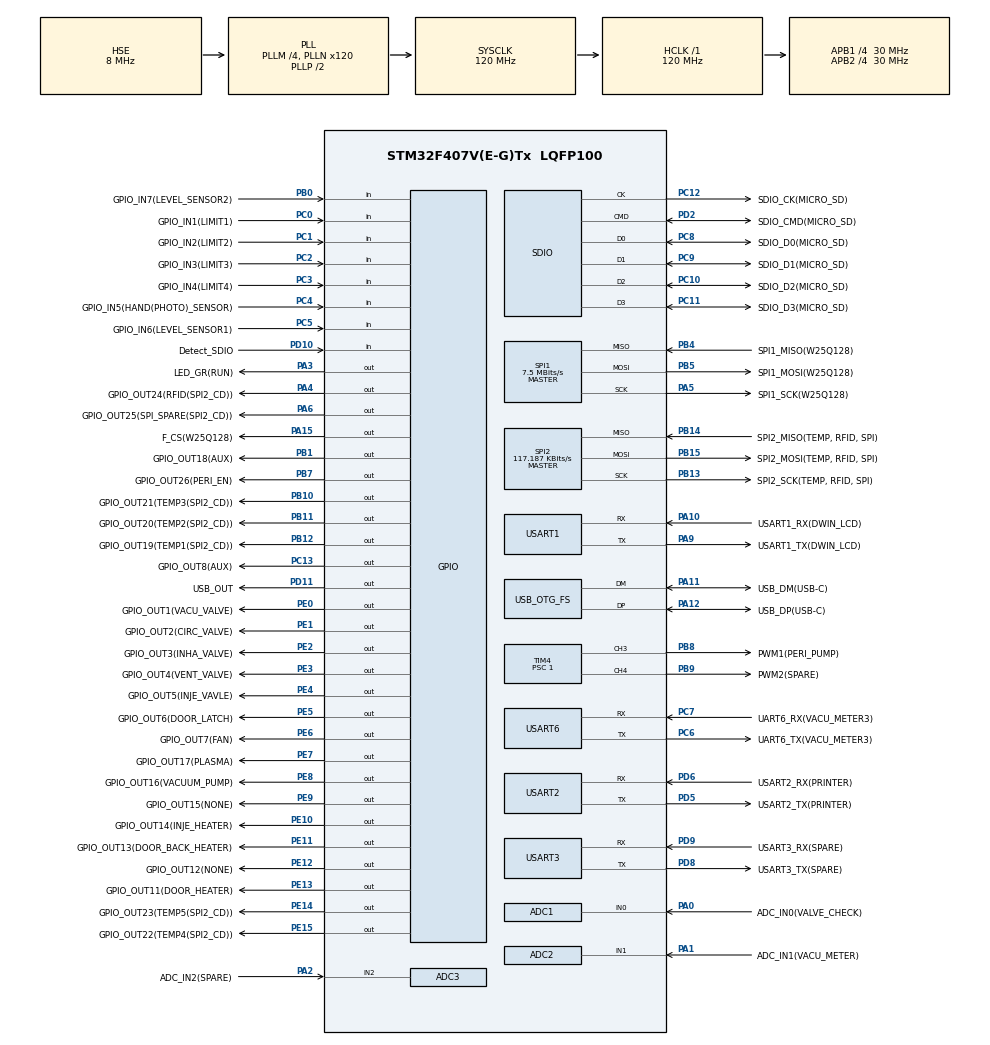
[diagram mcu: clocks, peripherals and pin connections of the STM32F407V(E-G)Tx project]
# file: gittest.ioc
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ADC1.Channel-3\#ChannelRegularConversion=ADC_CHANNEL_0
ADC1.Channel-4\#ChannelInjectedConversion=ADC_CHANNEL_0
ADC1.InjNumberOfConversion=1
ADC1.InjectedOffset-4\#ChannelInjectedConversion=0
ADC1.InjectedRank-4\#ChannelInjectedConversion=1
ADC1.NbrOfConversion=1
ADC1.NbrOfConversionFlag=1
ADC1.Rank-3\#ChannelRegularConversion=1
ADC1.SamplingTime-3\#ChannelRegularConversion=ADC_SAMPLETIME_3CYCLES
ADC1.SamplingTime-4\#ChannelInjectedConversion=ADC_SAMPLETIME_3CYCLES
ADC1.master=1
ADC2.Channel-5\#ChannelRegularConversion=ADC_CHANNEL_1
ADC2.Channel-6\#ChannelRegularConversion=ADC_CHANNEL_1
ADC2.Channel-7\#ChannelRegularConversion=ADC_CHANNEL_1
ADC2.Channel-8\#ChannelRegularConversion=ADC_CHANNEL_1
ADC2.Channel-9\#ChannelRegularConversion=ADC_CHANNEL_1
ADC2.ClockPrescaler=ADC_CLOCK_SYNC_PCLK_DIV2
ADC2.ContinuousConvMode=ENABLE
ADC2.DMAContinuousRequests=ENABLE
ADC2.NbrOfConversion=5
ADC2.NbrOfConversionFlag=1
ADC2.Rank-5\#ChannelRegularConversion=1
ADC2.Rank-6\#ChannelRegularConversion=2
ADC2.Rank-7\#ChannelRegularConversion=3
ADC2.Rank-8\#ChannelRegularConversion=4
ADC2.Rank-9\#ChannelRegularConversion=5
ADC2.SamplingTime-5\#ChannelRegularConversion=ADC_SAMPLETIME_15CYCLES
ADC2.SamplingTime-6\#ChannelRegularConversion=ADC_SAMPLETIME_15CYCLES
ADC2.SamplingTime-7\#ChannelRegularConversion=ADC_SAMPLETIME_15CYCLES
ADC2.SamplingTime-8\#ChannelRegularConversion=ADC_SAMPLETIME_15CYCLES
ADC2.SamplingTime-9\#ChannelRegularConversion=ADC_SAMPLETIME_15CYCLES
ADC2.ScanConvMode=ENABLE
ADC3.Channel-2\#ChannelRegularConversion=ADC_CHANNEL_2
ADC3.NbrOfConversionFlag=1
ADC3.Rank-2\#ChannelRegularConversion=1
ADC3.SamplingTime-2\#ChannelRegularConversion=ADC_SAMPLETIME_3CYCLES
Dma.ADC2.0.Direction=DMA_PERIPH_TO_MEMORY
Dma.ADC2.0.FIFOMode=DMA_FIFOMODE_DISABLE
Dma.ADC2.0.Instance=DMA2_Stream2
Dma.ADC2.0.MemDataAlignment=DMA_MDATAALIGN_WORD
Dma.ADC2.0.MemInc=DMA_MINC_ENABLE
Dma.ADC2.0.Mode=DMA_CIRCULAR
Dma.ADC2.0.PeriphDataAlignment=DMA_PDATAALIGN_WORD
Dma.ADC2.0.PeriphInc=DMA_PINC_DISABLE
Dma.ADC2.0.Priority=DMA_PRIORITY_LOW
Dma.Request0=ADC2
FATFS.BSP.number=1
FATFS._USE_LFN=1
FATFS0.BSP.STBoard=false
FATFS0.BSP.api=Unknown
FATFS0.BSP.instance=PD10
FATFS0.BSP.ip=GPIO
FATFS0.BSP.mode=Input
FATFS0.BSP.name=Detect_SDIO
FATFS0.BSP.solution=PD10
Mcu.Family=STM32F4
Mcu.Name=STM32F407V(E-G)Tx
Mcu.Package=LQFP100
NVIC.DMA2_Stream2_IRQn=true\:0\:0\:false\:false\:true\:false\:true\:true
NVIC.OTG_FS_IRQn=true\:0\:0\:false\:false\:true\:true\:true\:true
NVIC.PriorityGroup=NVIC_PRIORITYGROUP_4
NVIC.TIM7_IRQn=true\:0\:0\:false\:true\:true\:1\:true\:true\:true
NVIC.USART1_IRQn=true\:0\:0\:false\:true\:true\:2\:true\:true\:true
PA0-WKUP.GPIO_Label=ADC_IN0(VALVE_CHECK)
PA0-WKUP.Signal=ADCx_IN0
PA1.GPIO_Label=ADC_IN1(VACU_METER)
PA1.Signal=ADCx_IN1
PA10.GPIO_Label=USART1_RX(DWIN_LCD)
PA10.GPIO_PuPd=GPIO_PULLUP
PA10.Mode=Asynchronous
PA10.Signal=USART1_RX
PA11.GPIO_Label=USB_DM(USB-C)
PA11.GPIO_PuPd=GPIO_PULLUP
PA11.GPIO_Speed=GPIO_SPEED_FREQ_HIGH
PA11.Mode=Host_Only
PA11.Signal=USB_OTG_FS_DM
PA12.GPIO_Label=USB_DP(USB-C)
PA12.GPIO_PuPd=GPIO_PULLUP
PA12.GPIO_Speed=GPIO_SPEED_FREQ_HIGH
PA12.Mode=Host_Only
PA12.Signal=USB_OTG_FS_DP
PA13.Mode=Trace_Asynchronous_SW
PA13.Signal=SYS_JTMS-SWDIO
PA14.Mode=Trace_Asynchronous_SW
PA14.Signal=SYS_JTCK-SWCLK
PA15.GPIO_Label=F_CS(W25Q128)
PA15.Signal=GPIO_Output
PA2.GPIO_Label=ADC_IN2(SPARE)
PA2.Signal=ADCx_IN2
PA3.GPIO_Label=LED_GR(RUN)
PA3.Signal=GPIO_Output
PA4.GPIO_Label=GPIO_OUT24(RFID(SPI2_CD))
PA4.GPIO_PuPd=GPIO_PULLUP
PA4.GPIO_Speed=GPIO_SPEED_FREQ_VERY_HIGH
PA4.PinState=GPIO_PIN_SET
PA4.Signal=GPIO_Output
PA5.GPIO_Label=SPI1_SCK(W25Q128)
PA5.Mode=Full_Duplex_Master
PA5.Signal=SPI1_SCK
PA6.GPIO_Label=GPIO_OUT25(SPI_SPARE(SPI2_CD))
PA6.GPIO_PuPd=GPIO_PULLUP
PA6.GPIO_Speed=GPIO_SPEED_FREQ_VERY_HIGH
PA6.PinState=GPIO_PIN_SET
PA6.Signal=GPIO_Output
PA9.GPIO_Label=USART1_TX(DWIN_LCD)
PA9.GPIO_PuPd=GPIO_PULLUP
PA9.Mode=Asynchronous
PA9.Signal=USART1_TX
PB0.GPIO_Label=GPIO_IN7(LEVEL_SENSOR2)
PB0.Signal=GPIO_Input
PB1.GPIO_Label=GPIO_OUT18(AUX)
PB1.GPIO_ModeDefaultOutputPP=GPIO_MODE_OUTPUT_OD
PB1.PinState=GPIO_PIN_SET
PB1.Signal=GPIO_Output
PB10.GPIO_Label=GPIO_OUT21(TEMP3(SPI2_CD))
PB10.GPIO_PuPd=GPIO_PULLUP
PB10.GPIO_Speed=GPIO_SPEED_FREQ_VERY_HIGH
PB10.PinState=GPIO_PIN_SET
PB10.Signal=GPIO_Output
PB11.GPIO_Label=GPIO_OUT20(TEMP2(SPI2_CD))
PB11.GPIO_PuPd=GPIO_PULLUP
PB11.GPIO_Speed=GPIO_SPEED_FREQ_VERY_HIGH
PB11.PinState=GPIO_PIN_SET
PB11.Signal=GPIO_Output
PB12.GPIO_Label=GPIO_OUT19(TEMP1(SPI2_CD))
PB12.GPIO_PuPd=GPIO_PULLUP
PB12.GPIO_Speed=GPIO_SPEED_FREQ_VERY_HIGH
PB12.PinState=GPIO_PIN_SET
PB12.Signal=GPIO_Output
PB13.GPIO_Label=SPI2_SCK(TEMP, RFID, SPI)
PB13.Mode=Full_Duplex_Master
PB13.Signal=SPI2_SCK
PB14.GPIO_Label=SPI2_MISO(TEMP, RFID, SPI)
PB14.GPIO_PuPd=GPIO_PULLUP
PB14.Mode=Full_Duplex_Master
PB14.Signal=SPI2_MISO
PB15.GPIO_Label=SPI2_MOSI(TEMP, RFID, SPI)
PB15.GPIO_PuPd=GPIO_PULLUP
PB15.Mode=Full_Duplex_Master
PB15.Signal=SPI2_MOSI
PB3.Mode=Trace_Asynchronous_SW
PB3.Signal=SYS_JTDO-SWO
PB4.GPIO_Label=SPI1_MISO(W25Q128)
PB4.Mode=Full_Duplex_Master
PB4.Signal=SPI1_MISO
PB5.GPIO_Label=SPI1_MOSI(W25Q128)
PB5.Mode=Full_Duplex_Master
PB5.Signal=SPI1_MOSI
PB7.GPIO_Label=GPIO_OUT26(PERI_EN)
PB7.GPIO_ModeDefaultOutputPP=GPIO_MODE_OUTPUT_OD
PB7.PinState=GPIO_PIN_SET
PB7.Signal=GPIO_Output
PB8.GPIO_Label=PWM1(PERI_PUMP)
PB8.GPIO_ModeDefaultPP=GPIO_MODE_AF_PP
PB8.Signal=S_TIM4_CH3
PB9.GPIO_Label=PWM2(SPARE)
PB9.Signal=S_TIM4_CH4
PC0.GPIO_Label=GPIO_IN1(LIMIT1)
PC0.Signal=GPIO_Input
PC1.GPIO_Label=GPIO_IN2(LIMIT2)
PC1.Signal=GPIO_Input
PC10.GPIO_Label=SDIO_D2(MICRO_SD)
PC10.GPIO_PuPd=GPIO_PULLUP
PC10.Mode=SD_4_bits_Wide_bus
PC10.Signal=SDIO_D2
PC11.GPIO_Label=SDIO_D3(MICRO_SD)
PC11.GPIO_PuPd=GPIO_PULLUP
PC11.Mode=SD_4_bits_Wide_bus
PC11.Signal=SDIO_D3
PC12.GPIO_Label=SDIO_CK(MICRO_SD)
PC12.GPIO_PuPd=GPIO_PULLUP
PC12.Mode=SD_4_bits_Wide_bus
PC12.Signal=SDIO_CK
PC13-ANTI_TAMP.GPIO_Label=GPIO_OUT8(AUX)
PC13-ANTI_TAMP.Signal=GPIO_Output
PC2.GPIO_Label=GPIO_IN3(LIMIT3)
PC2.Signal=GPIO_Input
PC3.GPIO_Label=GPIO_IN4(LIMIT4)
PC3.Signal=GPIO_Input
PC4.GPIO_Label=GPIO_IN5(HAND(PHOTO)_SENSOR)
PC4.Signal=GPIO_Input
PC5.GPIO_Label=GPIO_IN6(LEVEL_SENSOR1)
PC5.Signal=GPIO_Input
PC6.GPIO_Label=UART6_TX(VACU_METER3)
PC6.Mode=Asynchronous
PC6.Signal=USART6_TX
PC7.GPIO_Label=UART6_RX(VACU_METER3)
PC7.Mode=Asynchronous
PC7.Signal=USART6_RX
PC8.GPIO_Label=SDIO_D0(MICRO_SD)
PC8.GPIO_PuPd=GPIO_PULLUP
PC8.Mode=SD_4_bits_Wide_bus
PC8.Signal=SDIO_D0
PC9.GPIO_Label=SDIO_D1(MICRO_SD)
PC9.GPIO_PuPd=GPIO_PULLUP
PC9.Mode=SD_4_bits_Wide_bus
PC9.Signal=SDIO_D1
PD10.GPIO_Label=Detect_SDIO
PD10.Signal=GPIO_Input
PD11.GPIO_Label=USB_OUT
PD11.Signal=GPIO_Output
PD2.GPIO_Label=SDIO_CMD(MICRO_SD)
PD2.GPIO_PuPd=GPIO_PULLUP
PD2.Mode=SD_4_bits_Wide_bus
PD2.Signal=SDIO_CMD
PD5.GPIO_Label=USART2_TX(PRINTER)
PD5.GPIO_PuPd=GPIO_PULLUP
PD5.Mode=Asynchronous
PD5.Signal=USART2_TX
PD6.GPIO_Label=USART2_RX(PRINTER)
PD6.GPIO_PuPd=GPIO_PULLUP
PD6.Mode=Asynchronous
PD6.Signal=USART2_RX
PD8.GPIO_Label=USART3_TX(SPARE)
PD8.Mode=Asynchronous
PD8.Signal=USART3_TX
PD9.GPIO_Label=USART3_RX(SPARE)
PD9.Mode=Asynchronous
PD9.Signal=USART3_RX
PE0.GPIO_Label=GPIO_OUT1(VACU_VALVE)
PE0.GPIO_ModeDefaultOutputPP=GPIO_MODE_OUTPUT_PP
PE0.GPIO_Speed=GPIO_SPEED_FREQ_VERY_HIGH
PE0.Signal=GPIO_Output
PE1.GPIO_Label=GPIO_OUT2(CIRC_VALVE)
PE1.Signal=GPIO_Output
PE10.GPIO_Label=GPIO_OUT14(INJE_HEATER)
PE10.GPIO_ModeDefaultOutputPP=GPIO_MODE_OUTPUT_OD
PE10.PinState=GPIO_PIN_SET
PE10.Signal=GPIO_Output
PE11.GPIO_Label=GPIO_OUT13(DOOR_BACK_HEATER)
PE11.GPIO_ModeDefaultOutputPP=GPIO_MODE_OUTPUT_OD
PE11.PinState=GPIO_PIN_SET
PE11.Signal=GPIO_Output
PE12.GPIO_Label=GPIO_OUT12(NONE)
PE12.GPIO_ModeDefaultOutputPP=GPIO_MODE_OUTPUT_OD
PE12.PinState=GPIO_PIN_SET
PE12.Signal=GPIO_Output
PE13.GPIO_Label=GPIO_OUT11(DOOR_HEATER)
PE13.GPIO_ModeDefaultOutputPP=GPIO_MODE_OUTPUT_OD
PE13.PinState=GPIO_PIN_SET
PE13.Signal=GPIO_Output
PE14.GPIO_Label=GPIO_OUT23(TEMP5(SPI2_CD))
PE14.GPIO_PuPd=GPIO_PULLUP
PE14.GPIO_Speed=GPIO_SPEED_FREQ_VERY_HIGH
PE14.PinState=GPIO_PIN_SET
PE14.Signal=GPIO_Output
PE15.GPIO_Label=GPIO_OUT22(TEMP4(SPI2_CD))
PE15.GPIO_PuPd=GPIO_PULLUP
PE15.GPIO_Speed=GPIO_SPEED_FREQ_VERY_HIGH
PE15.PinState=GPIO_PIN_SET
PE15.Signal=GPIO_Output
PE2.GPIO_Label=GPIO_OUT3(INHA_VALVE)
PE2.Signal=GPIO_Output
PE3.GPIO_Label=GPIO_OUT4(VENT_VALVE)
PE3.Signal=GPIO_Output
PE4.GPIO_Label=GPIO_OUT5(INJE_VAVLE)
PE4.Signal=GPIO_Output
PE5.GPIO_Label=GPIO_OUT6(DOOR_LATCH)
PE5.Signal=GPIO_Output
PE6.GPIO_Label=GPIO_OUT7(FAN)
PE6.Signal=GPIO_Output
PE7.GPIO_Label=GPIO_OUT17(PLASMA)
PE7.GPIO_ModeDefaultOutputPP=GPIO_MODE_OUTPUT_OD
PE7.PinState=GPIO_PIN_SET
PE7.Signal=GPIO_Output
PE8.GPIO_Label=GPIO_OUT16(VACUUM_PUMP)
PE8.GPIO_ModeDefaultOutputPP=GPIO_MODE_OUTPUT_OD
PE8.PinState=GPIO_PIN_SET
PE8.Signal=GPIO_Output
PE9.GPIO_Label=GPIO_OUT15(NONE)
PE9.GPIO_ModeDefaultOutputPP=GPIO_MODE_OUTPUT_OD
PE9.PinState=GPIO_PIN_SET
PE9.Signal=GPIO_Output
PH0-OSC_IN.Mode=HSE-External-Oscillator
PH0-OSC_IN.Signal=RCC_OSC_IN
PH1-OSC_OUT.Mode=HSE-External-Oscillator
PH1-OSC_OUT.Signal=RCC_OSC_OUT
ProjectManager.HeapSize=0x200
ProjectManager.StackSize=0x400
ProjectManager.TargetToolchain=STM32CubeIDE
RCC.48MHZClocksFreq_Value=48000000
RCC.AHBFreq_Value=120000000
RCC.APB1CLKDivider=RCC_HCLK_DIV4
RCC.APB1Freq_Value=30000000
RCC.APB1TimFreq_Value=60000000
RCC.APB2CLKDivider=RCC_HCLK_DIV4
RCC.APB2Freq_Value=30000000
RCC.APB2TimFreq_Value=60000000
RCC.CortexFreq_Value=120000000
RCC.HCLKFreq_Value=120000000
RCC.HSE_VALUE=8000000
RCC.HSI_VALUE=16000000
RCC.LSE_VALUE=32768
RCC.PLLM=4
RCC.PLLN=120
RCC.PLLQ=5
RCC.SYSCLKFreq_VALUE=120000000
RCC.SYSCLKSource=RCC_SYSCLKSOURCE_PLLCLK
RCC.VCOOutputFreq_Value=240000000
SDIO.ClockDiv=3
SH.ADCx_IN0.0=ADC1_IN0,IN0
SH.ADCx_IN1.0=ADC2_IN1,IN1
SH.ADCx_IN2.0=ADC3_IN2,IN2
SH.S_TIM4_CH3.0=TIM4_CH3,PWM Generation3 CH3
SH.S_TIM4_CH4.0=TIM4_CH4,PWM Generation4 CH4
SPI1.BaudRatePrescaler=SPI_BAUDRATEPRESCALER_4
SPI1.CalculateBaudRate=7.5 MBits/s
SPI1.Direction=SPI_DIRECTION_2LINES
SPI1.Mode=SPI_MODE_MASTER
SPI1.VirtualType=VM_MASTER
SPI2.BaudRatePrescaler=SPI_BAUDRATEPRESCALER_256
SPI2.CalculateBaudRate=117.187 KBits/s
SPI2.Direction=SPI_DIRECTION_2LINES
SPI2.Mode=SPI_MODE_MASTER
SPI2.VirtualType=VM_MASTER
TIM4.Channel-PWM\ Generation3\ CH3=TIM_CHANNEL_3
TIM4.Channel-PWM\ Generation4\ CH4=TIM_CHANNEL_4
TIM4.Period=20000-1
TIM4.Prescaler=1
TIM4.Pulse-PWM\ Generation3\ CH3=4000-1
TIM4.Pulse-PWM\ Generation4\ CH4=4000-1
TIM7.Period=6000-1
TIM7.Prescaler=10-1
USART1.VirtualMode=VM_ASYNC
USART2.VirtualMode=VM_ASYNC
USART3.VirtualMode=VM_ASYNC
USART6.VirtualMode=VM_ASYNC
USB_HOST.BSP.number=1
USB_HOST.SW_VBUS_DRIVE_MSC_FS=false
USB_HOST.USBH_HandleTypeDef-MSC_FS=hUsbHostFS
USB_HOST.VirtualModeFS=Msc
USB_HOST0.BSP.STBoard=false
USB_HOST0.BSP.api=Unknown
USB_HOST0.BSP.condition=SW_VBUS_DRIVE_MSC_FS \= false
USB_HOST0.BSP.instance=PD11
USB_HOST0.BSP.ip=GPIO
USB_HOST0.BSP.mode=Output
USB_HOST0.BSP.name=Drive_VBUS_FS
USB_HOST0.BSP.solution=PD11
USB_OTG_FS.VirtualMode=Host_Only
USB_OTG_FS.phy_itface=HCD_PHY_EMBEDDED
VP_CRC_VS_CRC.Mode=CRC_Activate
VP_FATFS_VS_SDIO.Mode=SDIO
VP_FATFS_VS_USB.Mode=USB
VP_RTC_VS_RTC_Activate.Mode=RTC_Enabled
VP_RTC_VS_RTC_Calendar.Mode=RTC_Calendar
VP_TIM7_VS_ClockSourceINT.Mode=Enable_Timer
VP_USB_HOST_VS_USB_HOST_MSC_FS.Mode=MSC_FS
board=custom

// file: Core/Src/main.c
/* USER CODE BEGIN Header */
/**
  ******************************************************************************
  * @file           : main.c
  * @brief          : Main program body
  ******************************************************************************
  * @attention
  *
  * Copyright (c) 2024 STMicroelectronics.
  * All rights reserved.
  *
  * This software is licensed under terms that can be found in the LICENSE file
  * in the root directory of this software component.
  * If no LICENSE file comes with this software, it is provided AS-IS.
  *
  ******************************************************************************
  */
/* USER CODE END Header */
#include "main.h"
#include "fatfs.h"
#include "usb_host.h"

/* USER CODE BEGIN Includes */
//이런식으로 수정하면 되나?
/* USER CODE END Includes */

ADC_HandleTypeDef hadc1;
ADC_HandleTypeDef hadc2;
ADC_HandleTypeDef hadc3;
DMA_HandleTypeDef hdma_adc2;

CRC_HandleTypeDef hcrc;

RTC_HandleTypeDef hrtc;

SD_HandleTypeDef hsd;

SPI_HandleTypeDef hspi1;
SPI_HandleTypeDef hspi2;

TIM_HandleTypeDef htim4;
TIM_HandleTypeDef htim7;

UART_HandleTypeDef huart1;
UART_HandleTypeDef huart2;
UART_HandleTypeDef huart3;
UART_HandleTypeDef huart6;

void SystemClock_Config(void);
static void MX_GPIO_Init(void);
static void MX_DMA_Init(void);
static void MX_RTC_Init(void);
static void MX_SDIO_SD_Init(void);
static void MX_SPI1_Init(void);
static void MX_SPI2_Init(void);
static void MX_TIM4_Init(void);
static void MX_TIM7_Init(void);
static void MX_USART1_UART_Init(void);
static void MX_USART2_UART_Init(void);
static void MX_USART3_UART_Init(void);
static void MX_USART6_UART_Init(void);
static void MX_ADC2_Init(void);
static void MX_ADC1_Init(void);
static void MX_ADC3_Init(void);
static void MX_CRC_Init(void);
static void MX_NVIC_Init(void);
void MX_USB_HOST_Process(void);

int main(void)
{

  /* MCU Configuration--------------------------------------------------------*/

  /* Reset of all peripherals, Initializes the Flash interface and the Systick. */
  HAL_Init();

  /* Configure the system clock */
  SystemClock_Config();

  /* Initialize all configured peripherals */
  MX_GPIO_Init();
  MX_DMA_Init();
  MX_RTC_Init();
  MX_SDIO_SD_Init();
  MX_SPI1_Init();
  MX_SPI2_Init();
  MX_TIM4_Init();
  MX_TIM7_Init();
  MX_USART1_UART_Init();
  MX_USART2_UART_Init();
  MX_USART3_UART_Init();
  MX_USART6_UART_Init();
  MX_ADC2_Init();
  MX_ADC1_Init();
  MX_ADC3_Init();
  MX_FATFS_Init();
  MX_CRC_Init();
  MX_USB_HOST_Init();

  /* Initialize interrupts */
  MX_NVIC_Init();

  /* Infinite loop */
  while (1)
  {
    MX_USB_HOST_Process();

  }
}

void SystemClock_Config(void)
{
  RCC_OscInitTypeDef RCC_OscInitStruct = {0};
  RCC_ClkInitTypeDef RCC_ClkInitStruct = {0};

  /** Configure the main internal regulator output voltage
  */
  __HAL_RCC_PWR_CLK_ENABLE();
  __HAL_PWR_VOLTAGESCALING_CONFIG(PWR_REGULATOR_VOLTAGE_SCALE1);

  /** Initializes the RCC Oscillators according to the specified parameters
  * in the RCC_OscInitTypeDef structure.
  */
  RCC_OscInitStruct.OscillatorType = RCC_OSCILLATORTYPE_LSI|RCC_OSCILLATORTYPE_HSE;
  RCC_OscInitStruct.HSEState = RCC_HSE_ON;
  RCC_OscInitStruct.LSIState = RCC_LSI_ON;
  RCC_OscInitStruct.PLL.PLLState = RCC_PLL_ON;
  RCC_OscInitStruct.PLL.PLLSource = RCC_PLLSOURCE_HSE;
  RCC_OscInitStruct.PLL.PLLM = 4;
  RCC_OscInitStruct.PLL.PLLN = 120;
  RCC_OscInitStruct.PLL.PLLP = RCC_PLLP_DIV2;
  RCC_OscInitStruct.PLL.PLLQ = 5;
  if (HAL_RCC_OscConfig(&RCC_OscInitStruct) != HAL_OK)
  {
    Error_Handler();
  }

  /** Initializes the CPU, AHB and APB buses clocks
  */
  RCC_ClkInitStruct.ClockType = RCC_CLOCKTYPE_HCLK|RCC_CLOCKTYPE_SYSCLK
                              |RCC_CLOCKTYPE_PCLK1|RCC_CLOCKTYPE_PCLK2;
  RCC_ClkInitStruct.SYSCLKSource = RCC_SYSCLKSOURCE_PLLCLK;
  RCC_ClkInitStruct.AHBCLKDivider = RCC_SYSCLK_DIV1;
  RCC_ClkInitStruct.APB1CLKDivider = RCC_HCLK_DIV4;
  RCC_ClkInitStruct.APB2CLKDivider = RCC_HCLK_DIV4;

  if (HAL_RCC_ClockConfig(&RCC_ClkInitStruct, FLASH_LATENCY_3) != HAL_OK)
  {
    Error_Handler();
  }
}

/**
  * @brief NVIC Configuration.
  * @retval None
  */
static void MX_NVIC_Init(void)
{
  /* TIM7_IRQn interrupt configuration */
  HAL_NVIC_SetPriority(TIM7_IRQn, 0, 0);
  HAL_NVIC_EnableIRQ(TIM7_IRQn);
  /* USART1_IRQn interrupt configuration */
  HAL_NVIC_SetPriority(USART1_IRQn, 0, 0);
  HAL_NVIC_EnableIRQ(USART1_IRQn);
}

static void MX_ADC1_Init(void)
{

  ADC_ChannelConfTypeDef sConfig = {0};
  ADC_InjectionConfTypeDef sConfigInjected = {0};

  /** Configure the global features of the ADC (Clock, Resolution, Data Alignment and number of conversion)
  */
  hadc1.Instance = ADC1;
  hadc1.Init.ClockPrescaler = ADC_CLOCK_SYNC_PCLK_DIV2;
  hadc1.Init.Resolution = ADC_RESOLUTION_12B;
  hadc1.Init.ScanConvMode = DISABLE;
  hadc1.Init.ContinuousConvMode = DISABLE;
  hadc1.Init.DiscontinuousConvMode = DISABLE;
  hadc1.Init.ExternalTrigConvEdge = ADC_EXTERNALTRIGCONVEDGE_NONE;
  hadc1.Init.ExternalTrigConv = ADC_SOFTWARE_START;
  hadc1.Init.DataAlign = ADC_DATAALIGN_RIGHT;
  hadc1.Init.NbrOfConversion = 1;
  hadc1.Init.DMAContinuousRequests = DISABLE;
  hadc1.Init.EOCSelection = ADC_EOC_SINGLE_CONV;
  if (HAL_ADC_Init(&hadc1) != HAL_OK)
  {
    Error_Handler();
  }

  /** Configure for the selected ADC regular channel its corresponding rank in the sequencer and its sample time.
  */
  sConfig.Channel = ADC_CHANNEL_0;
  sConfig.Rank = 1;
  sConfig.SamplingTime = ADC_SAMPLETIME_3CYCLES;
  if (HAL_ADC_ConfigChannel(&hadc1, &sConfig) != HAL_OK)
  {
    Error_Handler();
  }

  /** Configures for the selected ADC injected channel its corresponding rank in the sequencer and its sample time
  */
  sConfigInjected.InjectedChannel = ADC_CHANNEL_0;
  sConfigInjected.InjectedRank = 1;
  sConfigInjected.InjectedNbrOfConversion = 1;
  sConfigInjected.InjectedSamplingTime = ADC_SAMPLETIME_3CYCLES;
  sConfigInjected.ExternalTrigInjecConvEdge = ADC_EXTERNALTRIGINJECCONVEDGE_NONE;
  sConfigInjected.ExternalTrigInjecConv = ADC_INJECTED_SOFTWARE_START;
  sConfigInjected.AutoInjectedConv = DISABLE;
  sConfigInjected.InjectedDiscontinuousConvMode = DISABLE;
  sConfigInjected.InjectedOffset = 0;
  if (HAL_ADCEx_InjectedConfigChannel(&hadc1, &sConfigInjected) != HAL_OK)
  {
    Error_Handler();
  }

}

static void MX_ADC2_Init(void)
{

  ADC_ChannelConfTypeDef sConfig = {0};

  /** Configure the global features of the ADC (Clock, Resolution, Data Alignment and number of conversion)
  */
  hadc2.Instance = ADC2;
  hadc2.Init.ClockPrescaler = ADC_CLOCK_SYNC_PCLK_DIV2;
  hadc2.Init.Resolution = ADC_RESOLUTION_12B;
  hadc2.Init.ScanConvMode = ENABLE;
  hadc2.Init.ContinuousConvMode = ENABLE;
  hadc2.Init.DiscontinuousConvMode = DISABLE;
  hadc2.Init.ExternalTrigConvEdge = ADC_EXTERNALTRIGCONVEDGE_NONE;
  hadc2.Init.ExternalTrigConv = ADC_SOFTWARE_START;
  hadc2.Init.DataAlign = ADC_DATAALIGN_RIGHT;
  hadc2.Init.NbrOfConversion = 5;
  hadc2.Init.DMAContinuousRequests = ENABLE;
  hadc2.Init.EOCSelection = ADC_EOC_SINGLE_CONV;
  if (HAL_ADC_Init(&hadc2) != HAL_OK)
  {
    Error_Handler();
  }

  /** Configure for the selected ADC regular channel its corresponding rank in the sequencer and its sample time.
  */
  sConfig.Channel = ADC_CHANNEL_1;
  sConfig.Rank = 1;
  sConfig.SamplingTime = ADC_SAMPLETIME_15CYCLES;
  if (HAL_ADC_ConfigChannel(&hadc2, &sConfig) != HAL_OK)
  {
    Error_Handler();
  }

  /** Configure for the selected ADC regular channel its corresponding rank in the sequencer and its sample time.
  */
  sConfig.Rank = 2;
  if (HAL_ADC_ConfigChannel(&hadc2, &sConfig) != HAL_OK)
  {
    Error_Handler();
  }

  /** Configure for the selected ADC regular channel its corresponding rank in the sequencer and its sample time.
  */
  sConfig.Rank = 3;
  if (HAL_ADC_ConfigChannel(&hadc2, &sConfig) != HAL_OK)
  {
    Error_Handler();
  }

  /** Configure for the selected ADC regular channel its corresponding rank in the sequencer and its sample time.
  */
  sConfig.Rank = 4;
  if (HAL_ADC_ConfigChannel(&hadc2, &sConfig) != HAL_OK)
  {
    Error_Handler();
  }

  /** Configure for the selected ADC regular channel its corresponding rank in the sequencer and its sample time.
  */
  sConfig.Rank = 5;
  if (HAL_ADC_ConfigChannel(&hadc2, &sConfig) != HAL_OK)
  {
    Error_Handler();
  }

}

static void MX_ADC3_Init(void)
{

  ADC_ChannelConfTypeDef sConfig = {0};

  /** Configure the global features of the ADC (Clock, Resolution, Data Alignment and number of conversion)
  */
  hadc3.Instance = ADC3;
  hadc3.Init.ClockPrescaler = ADC_CLOCK_SYNC_PCLK_DIV2;
  hadc3.Init.Resolution = ADC_RESOLUTION_12B;
  hadc3.Init.ScanConvMode = DISABLE;
  hadc3.Init.ContinuousConvMode = DISABLE;
  hadc3.Init.DiscontinuousConvMode = DISABLE;
  hadc3.Init.ExternalTrigConvEdge = ADC_EXTERNALTRIGCONVEDGE_NONE;
  hadc3.Init.ExternalTrigConv = ADC_SOFTWARE_START;
  hadc3.Init.DataAlign = ADC_DATAALIGN_RIGHT;
  hadc3.Init.NbrOfConversion = 1;
  hadc3.Init.DMAContinuousRequests = DISABLE;
  hadc3.Init.EOCSelection = ADC_EOC_SINGLE_CONV;
  if (HAL_ADC_Init(&hadc3) != HAL_OK)
  {
    Error_Handler();
  }

  /** Configure for the selected ADC regular channel its corresponding rank in the sequencer and its sample time.
  */
  sConfig.Channel = ADC_CHANNEL_2;
  sConfig.Rank = 1;
  sConfig.SamplingTime = ADC_SAMPLETIME_3CYCLES;
  if (HAL_ADC_ConfigChannel(&hadc3, &sConfig) != HAL_OK)
  {
    Error_Handler();
  }

}

static void MX_CRC_Init(void)
{

  hcrc.Instance = CRC;
  if (HAL_CRC_Init(&hcrc) != HAL_OK)
  {
    Error_Handler();
  }

}

static void MX_RTC_Init(void)
{

  RTC_TimeTypeDef sTime = {0};
  RTC_DateTypeDef sDate = {0};

  /** Initialize RTC Only
  */
  hrtc.Instance = RTC;
  hrtc.Init.HourFormat = RTC_HOURFORMAT_24;
  hrtc.Init.AsynchPrediv = 127;
  hrtc.Init.SynchPrediv = 255;
  hrtc.Init.OutPut = RTC_OUTPUT_DISABLE;
  hrtc.Init.OutPutPolarity = RTC_OUTPUT_POLARITY_HIGH;
  hrtc.Init.OutPutType = RTC_OUTPUT_TYPE_OPENDRAIN;
  if (HAL_RTC_Init(&hrtc) != HAL_OK)
  {
    Error_Handler();
  }

  /** Initialize RTC and set the Time and Date
  */
  sTime.Hours = 0x0;
  sTime.Minutes = 0x0;
  sTime.Seconds = 0x0;
  sTime.DayLightSaving = RTC_DAYLIGHTSAVING_NONE;
  sTime.StoreOperation = RTC_STOREOPERATION_RESET;
  if (HAL_RTC_SetTime(&hrtc, &sTime, RTC_FORMAT_BCD) != HAL_OK)
  {
    Error_Handler();
  }
  sDate.WeekDay = RTC_WEEKDAY_MONDAY;
  sDate.Month = RTC_MONTH_JANUARY;
  sDate.Date = 0x1;
  sDate.Year = 0x0;

  if (HAL_RTC_SetDate(&hrtc, &sDate, RTC_FORMAT_BCD) != HAL_OK)
  {
    Error_Handler();
  }

}

static void MX_SDIO_SD_Init(void)
{

  hsd.Instance = SDIO;
  hsd.Init.ClockEdge = SDIO_CLOCK_EDGE_RISING;
  hsd.Init.ClockBypass = SDIO_CLOCK_BYPASS_DISABLE;
  hsd.Init.ClockPowerSave = SDIO_CLOCK_POWER_SAVE_DISABLE;
  hsd.Init.BusWide = SDIO_BUS_WIDE_4B;
  hsd.Init.HardwareFlowControl = SDIO_HARDWARE_FLOW_CONTROL_DISABLE;
  hsd.Init.ClockDiv = 3;

}

static void MX_SPI1_Init(void)
{

  /* SPI1 parameter configuration*/
  hspi1.Instance = SPI1;
  hspi1.Init.Mode = SPI_MODE_MASTER;
  hspi1.Init.Direction = SPI_DIRECTION_2LINES;
  hspi1.Init.DataSize = SPI_DATASIZE_8BIT;
  hspi1.Init.CLKPolarity = SPI_POLARITY_LOW;
  hspi1.Init.CLKPhase = SPI_PHASE_1EDGE;
  hspi1.Init.NSS = SPI_NSS_SOFT;
  hspi1.Init.BaudRatePrescaler = SPI_BAUDRATEPRESCALER_4;
  hspi1.Init.FirstBit = SPI_FIRSTBIT_MSB;
  hspi1.Init.TIMode = SPI_TIMODE_DISABLE;
  hspi1.Init.CRCCalculation = SPI_CRCCALCULATION_DISABLE;
  hspi1.Init.CRCPolynomial = 10;
  if (HAL_SPI_Init(&hspi1) != HAL_OK)
  {
    Error_Handler();
  }

}

static void MX_SPI2_Init(void)
{

  /* SPI2 parameter configuration*/
  hspi2.Instance = SPI2;
  hspi2.Init.Mode = SPI_MODE_MASTER;
  hspi2.Init.Direction = SPI_DIRECTION_2LINES;
  hspi2.Init.DataSize = SPI_DATASIZE_8BIT;
  hspi2.Init.CLKPolarity = SPI_POLARITY_LOW;
  hspi2.Init.CLKPhase = SPI_PHASE_1EDGE;
  hspi2.Init.NSS = SPI_NSS_SOFT;
  hspi2.Init.BaudRatePrescaler = SPI_BAUDRATEPRESCALER_256;
  hspi2.Init.FirstBit = SPI_FIRSTBIT_MSB;
  hspi2.Init.TIMode = SPI_TIMODE_DISABLE;
  hspi2.Init.CRCCalculation = SPI_CRCCALCULATION_DISABLE;
  hspi2.Init.CRCPolynomial = 10;
  if (HAL_SPI_Init(&hspi2) != HAL_OK)
  {
    Error_Handler();
  }

}

static void MX_TIM4_Init(void)
{

  TIM_MasterConfigTypeDef sMasterConfig = {0};
  TIM_OC_InitTypeDef sConfigOC = {0};

  htim4.Instance = TIM4;
  htim4.Init.Prescaler = 1;
  htim4.Init.CounterMode = TIM_COUNTERMODE_UP;
  htim4.Init.Period = 20000-1;
  htim4.Init.ClockDivision = TIM_CLOCKDIVISION_DIV1;
  htim4.Init.AutoReloadPreload = TIM_AUTORELOAD_PRELOAD_DISABLE;
  if (HAL_TIM_PWM_Init(&htim4) != HAL_OK)
  {
    Error_Handler();
  }
  sMasterConfig.MasterOutputTrigger = TIM_TRGO_RESET;
  sMasterConfig.MasterSlaveMode = TIM_MASTERSLAVEMODE_DISABLE;
  if (HAL_TIMEx_MasterConfigSynchronization(&htim4, &sMasterConfig) != HAL_OK)
  {
    Error_Handler();
  }
  sConfigOC.OCMode = TIM_OCMODE_PWM1;
  sConfigOC.Pulse = 4000-1;
  sConfigOC.OCPolarity = TIM_OCPOLARITY_HIGH;
  sConfigOC.OCFastMode = TIM_OCFAST_DISABLE;
  if (HAL_TIM_PWM_ConfigChannel(&htim4, &sConfigOC, TIM_CHANNEL_3) != HAL_OK)
  {
    Error_Handler();
  }
  if (HAL_TIM_PWM_ConfigChannel(&htim4, &sConfigOC, TIM_CHANNEL_4) != HAL_OK)
  {
    Error_Handler();
  }
  HAL_TIM_MspPostInit(&htim4);

}

static void MX_TIM7_Init(void)
{

  TIM_MasterConfigTypeDef sMasterConfig = {0};

  htim7.Instance = TIM7;
  htim7.Init.Prescaler = 10-1;
  htim7.Init.CounterMode = TIM_COUNTERMODE_UP;
  htim7.Init.Period = 6000-1;
  htim7.Init.AutoReloadPreload = TIM_AUTORELOAD_PRELOAD_DISABLE;
  if (HAL_TIM_Base_Init(&htim7) != HAL_OK)
  {
    Error_Handler();
  }
  sMasterConfig.MasterOutputTrigger = TIM_TRGO_RESET;
  sMasterConfig.MasterSlaveMode = TIM_MASTERSLAVEMODE_DISABLE;
  if (HAL_TIMEx_MasterConfigSynchronization(&htim7, &sMasterConfig) != HAL_OK)
  {
    Error_Handler();
  }

}

static void MX_USART1_UART_Init(void)
{

  huart1.Instance = USART1;
  huart1.Init.BaudRate = 115200;
  huart1.Init.WordLength = UART_WORDLENGTH_8B;
  huart1.Init.StopBits = UART_STOPBITS_1;
  huart1.Init.Parity = UART_PARITY_NONE;
  huart1.Init.Mode = UART_MODE_TX_RX;
  huart1.Init.HwFlowCtl = UART_HWCONTROL_NONE;
  huart1.Init.OverSampling = UART_OVERSAMPLING_16;
  if (HAL_UART_Init(&huart1) != HAL_OK)
  {
    Error_Handler();
  }

}

static void MX_USART2_UART_Init(void)
{

  huart2.Instance = USART2;
  huart2.Init.BaudRate = 115200;
  huart2.Init.WordLength = UART_WORDLENGTH_8B;
  huart2.Init.StopBits = UART_STOPBITS_1;
  huart2.Init.Parity = UART_PARITY_NONE;
  huart2.Init.Mode = UART_MODE_TX_RX;
  huart2.Init.HwFlowCtl = UART_HWCONTROL_NONE;
  huart2.Init.OverSampling = UART_OVERSAMPLING_16;
  if (HAL_UART_Init(&huart2) != HAL_OK)
  {
    Error_Handler();
  }

}

static void MX_USART3_UART_Init(void)
{

  huart3.Instance = USART3;
  huart3.Init.BaudRate = 115200;
  huart3.Init.WordLength = UART_WORDLENGTH_8B;
  huart3.Init.StopBits = UART_STOPBITS_1;
  huart3.Init.Parity = UART_PARITY_NONE;
  huart3.Init.Mode = UART_MODE_TX_RX;
  huart3.Init.HwFlowCtl = UART_HWCONTROL_NONE;
  huart3.Init.OverSampling = UART_OVERSAMPLING_16;
  if (HAL_UART_Init(&huart3) != HAL_OK)
  {
    Error_Handler();
  }

}

static void MX_USART6_UART_Init(void)
{

  huart6.Instance = USART6;
  huart6.Init.BaudRate = 115200;
  huart6.Init.WordLength = UART_WORDLENGTH_8B;
  huart6.Init.StopBits = UART_STOPBITS_1;
  huart6.Init.Parity = UART_PARITY_NONE;
  huart6.Init.Mode = UART_MODE_TX_RX;
  huart6.Init.HwFlowCtl = UART_HWCONTROL_NONE;
  huart6.Init.OverSampling = UART_OVERSAMPLING_16;
  if (HAL_UART_Init(&huart6) != HAL_OK)
  {
    Error_Handler();
  }

}

static void MX_DMA_Init(void)
{

  /* DMA controller clock enable */
  __HAL_RCC_DMA2_CLK_ENABLE();

  /* DMA interrupt init */
  /* DMA2_Stream2_IRQn interrupt configuration */
  HAL_NVIC_SetPriority(DMA2_Stream2_IRQn, 0, 0);
  HAL_NVIC_EnableIRQ(DMA2_Stream2_IRQn);

}

static void MX_GPIO_Init(void)
{
  GPIO_InitTypeDef GPIO_InitStruct = {0};

  /* GPIO Ports Clock Enable */
  __HAL_RCC_GPIOE_CLK_ENABLE();
  __HAL_RCC_GPIOC_CLK_ENABLE();
  __HAL_RCC_GPIOH_CLK_ENABLE();
  __HAL_RCC_GPIOA_CLK_ENABLE();
  __HAL_RCC_GPIOB_CLK_ENABLE();
  __HAL_RCC_GPIOD_CLK_ENABLE();

  /*Configure GPIO pin Output Level */
  HAL_GPIO_WritePin(GPIOE, GPIO_OUT3_Pin|GPIO_OUT4_Pin|GPIO_OUT5_Pin|GPIO_OUT6_Pin
                          |GPIO_OUT7_Pin|GPIO_OUT1_Pin|GPIO_OUT2_Pin, GPIO_PIN_RESET);

  /*Configure GPIO pin Output Level */
  HAL_GPIO_WritePin(GPIO_OUT8_GPIO_Port, GPIO_OUT8_Pin, GPIO_PIN_RESET);

  /*Configure GPIO pin Output Level */
  HAL_GPIO_WritePin(GPIOA, LED_GR_Pin|F_CS_Pin, GPIO_PIN_RESET);

  /*Configure GPIO pin Output Level */
  HAL_GPIO_WritePin(GPIOA, GPIO_OUT24_Pin|GPIO_OUT25_Pin, GPIO_PIN_SET);

  /*Configure GPIO pin Output Level */
  HAL_GPIO_WritePin(GPIOB, GPIO_OUT18_Pin|GPIO_OUT21_Pin|GPIO_OUT20_Pin|GPIO_OUT19_Pin
                          |GPIO_OUT26_Pin, GPIO_PIN_SET);

  /*Configure GPIO pin Output Level */
  HAL_GPIO_WritePin(GPIOE, GPIO_OUT17_Pin|GPIO_OUT16_Pin|GPIO_OUT15_Pin|GPIO_OUT14_Pin
                          |GPIO_OUT13_Pin|GPIO_OUT12_Pin|GPIO_OUT11_Pin|GPIO_OUT23_Pin
                          |GPIO_OUT22_Pin, GPIO_PIN_SET);

  /*Configure GPIO pin Output Level */
  HAL_GPIO_WritePin(USB_OUT_GPIO_Port, USB_OUT_Pin, GPIO_PIN_RESET);

  /*Configure GPIO pins : GPIO_OUT3_Pin GPIO_OUT4_Pin GPIO_OUT5_Pin GPIO_OUT6_Pin
                           GPIO_OUT7_Pin GPIO_OUT2_Pin */
  GPIO_InitStruct.Pin = GPIO_OUT3_Pin|GPIO_OUT4_Pin|GPIO_OUT5_Pin|GPIO_OUT6_Pin
                          |GPIO_OUT7_Pin|GPIO_OUT2_Pin;
  GPIO_InitStruct.Mode = GPIO_MODE_OUTPUT_PP;
  GPIO_InitStruct.Pull = GPIO_NOPULL;
  GPIO_InitStruct.Speed = GPIO_SPEED_FREQ_LOW;
  HAL_GPIO_Init(GPIOE, &GPIO_InitStruct);

  /*Configure GPIO pin : GPIO_OUT8_Pin */
  GPIO_InitStruct.Pin = GPIO_OUT8_Pin;
  GPIO_InitStruct.Mode = GPIO_MODE_OUTPUT_PP;
  GPIO_InitStruct.Pull = GPIO_NOPULL;
  GPIO_InitStruct.Speed = GPIO_SPEED_FREQ_LOW;
  HAL_GPIO_Init(GPIO_OUT8_GPIO_Port, &GPIO_InitStruct);

  /*Configure GPIO pins : GPIO_IN1_Pin GPIO_IN2_Pin GPIO_IN3_Pin GPIO_IN4_Pin
                           GPIO_IN5_Pin GPIO_IN6_Pin */
  GPIO_InitStruct.Pin = GPIO_IN1_Pin|GPIO_IN2_Pin|GPIO_IN3_Pin|GPIO_IN4_Pin
                          |GPIO_IN5_Pin|GPIO_IN6_Pin;
  GPIO_InitStruct.Mode = GPIO_MODE_INPUT;
  GPIO_InitStruct.Pull = GPIO_NOPULL;
  HAL_GPIO_Init(GPIOC, &GPIO_InitStruct);

  /*Configure GPIO pins : LED_GR_Pin F_CS_Pin */
  GPIO_InitStruct.Pin = LED_GR_Pin|F_CS_Pin;
  GPIO_InitStruct.Mode = GPIO_MODE_OUTPUT_PP;
  GPIO_InitStruct.Pull = GPIO_NOPULL;
  GPIO_InitStruct.Speed = GPIO_SPEED_FREQ_LOW;
  HAL_GPIO_Init(GPIOA, &GPIO_InitStruct);

  /*Configure GPIO pins : GPIO_OUT24_Pin GPIO_OUT25_Pin */
  GPIO_InitStruct.Pin = GPIO_OUT24_Pin|GPIO_OUT25_Pin;
  GPIO_InitStruct.Mode = GPIO_MODE_OUTPUT_PP;
  GPIO_InitStruct.Pull = GPIO_PULLUP;
  GPIO_InitStruct.Speed = GPIO_SPEED_FREQ_VERY_HIGH;
  HAL_GPIO_Init(GPIOA, &GPIO_InitStruct);

  /*Configure GPIO pin : GPIO_IN7_Pin */
  GPIO_InitStruct.Pin = GPIO_IN7_Pin;
  GPIO_InitStruct.Mode = GPIO_MODE_INPUT;
  GPIO_InitStruct.Pull = GPIO_NOPULL;
  HAL_GPIO_Init(GPIO_IN7_GPIO_Port, &GPIO_InitStruct);

  /*Configure GPIO pins : GPIO_OUT18_Pin GPIO_OUT26_Pin */
  GPIO_InitStruct.Pin = GPIO_OUT18_Pin|GPIO_OUT26_Pin;
  GPIO_InitStruct.Mode = GPIO_MODE_OUTPUT_OD;
  GPIO_InitStruct.Pull = GPIO_NOPULL;
  GPIO_InitStruct.Speed = GPIO_SPEED_FREQ_LOW;
  HAL_GPIO_Init(GPIOB, &GPIO_InitStruct);

  /*Configure GPIO pins : GPIO_OUT17_Pin GPIO_OUT16_Pin GPIO_OUT15_Pin GPIO_OUT14_Pin
                           GPIO_OUT13_Pin GPIO_OUT12_Pin GPIO_OUT11_Pin */
  GPIO_InitStruct.Pin = GPIO_OUT17_Pin|GPIO_OUT16_Pin|GPIO_OUT15_Pin|GPIO_OUT14_Pin
                          |GPIO_OUT13_Pin|GPIO_OUT12_Pin|GPIO_OUT11_Pin;
  GPIO_InitStruct.Mode = GPIO_MODE_OUTPUT_OD;
  GPIO_InitStruct.Pull = GPIO_NOPULL;
  GPIO_InitStruct.Speed = GPIO_SPEED_FREQ_LOW;
  HAL_GPIO_Init(GPIOE, &GPIO_InitStruct);

  /*Configure GPIO pins : GPIO_OUT23_Pin GPIO_OUT22_Pin */
  GPIO_InitStruct.Pin = GPIO_OUT23_Pin|GPIO_OUT22_Pin;
  GPIO_InitStruct.Mode = GPIO_MODE_OUTPUT_PP;
  GPIO_InitStruct.Pull = GPIO_PULLUP;
  GPIO_InitStruct.Speed = GPIO_SPEED_FREQ_VERY_HIGH;
  HAL_GPIO_Init(GPIOE, &GPIO_InitStruct);

  /*Configure GPIO pins : GPIO_OUT21_Pin GPIO_OUT20_Pin GPIO_OUT19_Pin */
  GPIO_InitStruct.Pin = GPIO_OUT21_Pin|GPIO_OUT20_Pin|GPIO_OUT19_Pin;
  GPIO_InitStruct.Mode = GPIO_MODE_OUTPUT_PP;
  GPIO_InitStruct.Pull = GPIO_PULLUP;
  GPIO_InitStruct.Speed = GPIO_SPEED_FREQ_VERY_HIGH;
  HAL_GPIO_Init(GPIOB, &GPIO_InitStruct);

  /*Configure GPIO pin : Detect_SDIO_Pin */
  GPIO_InitStruct.Pin = Detect_SDIO_Pin;
  GPIO_InitStruct.Mode = GPIO_MODE_INPUT;
  GPIO_InitStruct.Pull = GPIO_NOPULL;
  HAL_GPIO_Init(Detect_SDIO_GPIO_Port, &GPIO_InitStruct);

  /*Configure GPIO pin : USB_OUT_Pin */
  GPIO_InitStruct.Pin = USB_OUT_Pin;
  GPIO_InitStruct.Mode = GPIO_MODE_OUTPUT_PP;
  GPIO_InitStruct.Pull = GPIO_NOPULL;
  GPIO_InitStruct.Speed = GPIO_SPEED_FREQ_LOW;
  HAL_GPIO_Init(USB_OUT_GPIO_Port, &GPIO_InitStruct);

  /*Configure GPIO pin : GPIO_OUT1_Pin */
  GPIO_InitStruct.Pin = GPIO_OUT1_Pin;
  GPIO_InitStruct.Mode = GPIO_MODE_OUTPUT_PP;
  GPIO_InitStruct.Pull = GPIO_NOPULL;
  GPIO_InitStruct.Speed = GPIO_SPEED_FREQ_VERY_HIGH;
  HAL_GPIO_Init(GPIO_OUT1_GPIO_Port, &GPIO_InitStruct);

}

void Error_Handler(void)
{
  __disable_irq();
  while (1)
  {
  }
}
